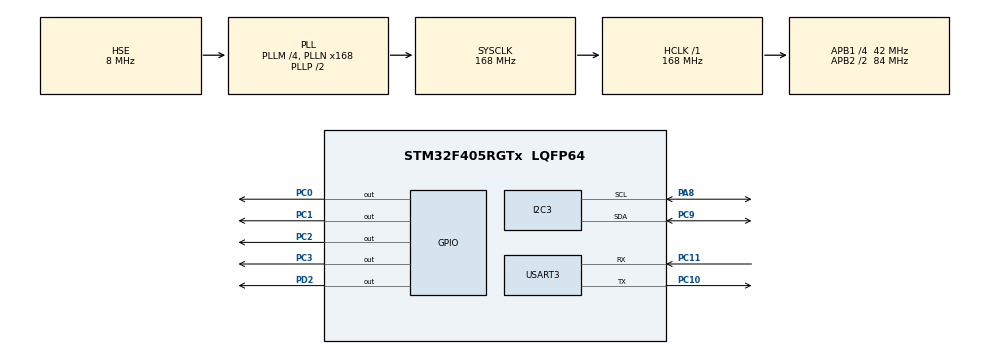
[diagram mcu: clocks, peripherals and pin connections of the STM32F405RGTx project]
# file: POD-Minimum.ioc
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Dma.I2C3_RX.0.Direction=DMA_PERIPH_TO_MEMORY
Dma.I2C3_RX.0.FIFOMode=DMA_FIFOMODE_DISABLE
Dma.I2C3_RX.0.Instance=DMA1_Stream2
Dma.I2C3_RX.0.MemDataAlignment=DMA_MDATAALIGN_BYTE
Dma.I2C3_RX.0.MemInc=DMA_MINC_ENABLE
Dma.I2C3_RX.0.Mode=DMA_NORMAL
Dma.I2C3_RX.0.PeriphDataAlignment=DMA_PDATAALIGN_BYTE
Dma.I2C3_RX.0.PeriphInc=DMA_PINC_DISABLE
Dma.I2C3_RX.0.Priority=DMA_PRIORITY_LOW
Dma.Request0=I2C3_RX
FREERTOS.Tasks01=defaultTask,24,150,StartDefaultTask,Default,NULL,Dynamic,NULL,NULL
FREERTOS.configENABLE_FPU=1
FREERTOS.configIDLE_SHOULD_YIELD=1
FREERTOS.configMINIMAL_STACK_SIZE=150
FREERTOS.configUSE_IDLE_HOOK=1
I2C3.I2C_Mode=I2C_Fast
I2C3.OwnAddress=0
Mcu.Family=STM32F4
Mcu.Name=STM32F405RGTx
Mcu.Package=LQFP64
NVIC.DMA1_Stream2_IRQn=true\:7\:0\:true\:false\:true\:true\:false\:true\:true
NVIC.I2C3_ER_IRQn=true\:7\:0\:true\:false\:true\:true\:true\:true\:true
NVIC.I2C3_EV_IRQn=true\:7\:0\:true\:false\:true\:true\:true\:true\:true
NVIC.PriorityGroup=NVIC_PRIORITYGROUP_4
NVIC.TIM6_DAC_IRQn=true\:15\:0\:false\:false\:true\:false\:false\:true\:true
NVIC.TIM7_IRQn=true\:5\:0\:true\:false\:true\:true\:true\:true\:true
NVIC.TimeBase=TIM6_DAC_IRQn
NVIC.TimeBaseIP=TIM6
NVIC.USART3_IRQn=true\:5\:0\:false\:false\:true\:true\:true\:true\:true
PA8.Mode=I2C
PA8.Signal=I2C3_SCL
PC0.GPIO_Speed=GPIO_SPEED_FREQ_MEDIUM
PC0.Signal=GPIO_Output
PC1.GPIO_Speed=GPIO_SPEED_FREQ_MEDIUM
PC1.Signal=GPIO_Output
PC10.Mode=Asynchronous
PC10.Signal=USART3_TX
PC11.Mode=Asynchronous
PC11.Signal=USART3_RX
PC2.GPIO_Speed=GPIO_SPEED_FREQ_MEDIUM
PC2.Signal=GPIO_Output
PC3.GPIO_Speed=GPIO_SPEED_FREQ_MEDIUM
PC3.Signal=GPIO_Output
PC9.Mode=I2C
PC9.Signal=I2C3_SDA
PD2.Signal=GPIO_Output
PH0-OSC_IN.Mode=HSE-External-Oscillator
PH0-OSC_IN.Signal=RCC_OSC_IN
PH1-OSC_OUT.Mode=HSE-External-Oscillator
PH1-OSC_OUT.Signal=RCC_OSC_OUT
ProjectManager.HeapSize=0x200
ProjectManager.StackSize=0x400
ProjectManager.TargetToolchain=Makefile
RCC.48MHZClocksFreq_Value=48000000
RCC.AHBFreq_Value=168000000
RCC.APB1CLKDivider=RCC_HCLK_DIV4
RCC.APB1Freq_Value=42000000
RCC.APB1TimFreq_Value=84000000
RCC.APB2CLKDivider=RCC_HCLK_DIV2
RCC.APB2Freq_Value=84000000
RCC.APB2TimFreq_Value=168000000
RCC.CortexFreq_Value=168000000
RCC.HCLKFreq_Value=168000000
RCC.HSE_VALUE=8000000
RCC.HSI_VALUE=16000000
RCC.LSE_VALUE=32768
RCC.PLLM=4
RCC.PLLN=168
RCC.PLLQ=7
RCC.PLLSourceVirtual=RCC_PLLSOURCE_HSE
RCC.SYSCLKFreq_VALUE=168000000
RCC.SYSCLKSource=RCC_SYSCLKSOURCE_PLLCLK
RCC.VCOOutputFreq_Value=336000000
TIM7.Prescaler=84
TIM7.TIM_MasterOutputTrigger=TIM_TRGO_RESET
USART3.VirtualMode=VM_ASYNC
VP_FREERTOS_VS_CMSIS_V2.Mode=CMSIS_V2
VP_SYS_VS_tim6.Mode=TIM6
VP_TIM7_VS_ClockSourceINT.Mode=Enable_Timer
board=custom

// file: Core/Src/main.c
/* USER CODE BEGIN Header */
/**
  ******************************************************************************
  * @file           : main.c
  * @brief          : Main program body
  ******************************************************************************
  * @attention
  *
  * Copyright (c) 2023 STMicroelectronics.
  * All rights reserved.
  *
  * This software is licensed under terms that can be found in the LICENSE file
  * in the root directory of this software component.
  * If no LICENSE file comes with this software, it is provided AS-IS.
  *
  ******************************************************************************
  */
/* USER CODE END Header */
#include "main.h"
#include "cmsis_os.h"
#include "dma.h"
#include "i2c.h"
#include "tim.h"
#include "usart.h"
#include "gpio.h"

void SystemClock_Config(void);
void MX_FREERTOS_Init(void);

int main(void)
{

  /* MCU Configuration--------------------------------------------------------*/

  /* Reset of all peripherals, Initializes the Flash interface and the Systick. */
  HAL_Init();

  /* Configure the system clock */
  SystemClock_Config();

  /* Initialize all configured peripherals */
  MX_GPIO_Init();
  MX_USART3_UART_Init();
  MX_DMA_Init();
  MX_TIM7_Init();
  MX_I2C3_Init();

  /* Init scheduler */
  osKernelInitialize();  /* Call init function for freertos objects (in freertos.c) */
  MX_FREERTOS_Init();

  /* Start scheduler */
  osKernelStart();

  /* We should never get here as control is now taken by the scheduler */
  /* Infinite loop */
  while (1)
  {

  }
}

void SystemClock_Config(void)
{
  RCC_OscInitTypeDef RCC_OscInitStruct = {0};
  RCC_ClkInitTypeDef RCC_ClkInitStruct = {0};

  /** Configure the main internal regulator output voltage
  */
  __HAL_RCC_PWR_CLK_ENABLE();
  __HAL_PWR_VOLTAGESCALING_CONFIG(PWR_REGULATOR_VOLTAGE_SCALE1);

  /** Initializes the RCC Oscillators according to the specified parameters
  * in the RCC_OscInitTypeDef structure.
  */
  RCC_OscInitStruct.OscillatorType = RCC_OSCILLATORTYPE_HSE;
  RCC_OscInitStruct.HSEState = RCC_HSE_ON;
  RCC_OscInitStruct.PLL.PLLState = RCC_PLL_ON;
  RCC_OscInitStruct.PLL.PLLSource = RCC_PLLSOURCE_HSE;
  RCC_OscInitStruct.PLL.PLLM = 4;
  RCC_OscInitStruct.PLL.PLLN = 168;
  RCC_OscInitStruct.PLL.PLLP = RCC_PLLP_DIV2;
  RCC_OscInitStruct.PLL.PLLQ = 7;
  if (HAL_RCC_OscConfig(&RCC_OscInitStruct) != HAL_OK)
  {
    Error_Handler();
  }

  /** Initializes the CPU, AHB and APB buses clocks
  */
  RCC_ClkInitStruct.ClockType = RCC_CLOCKTYPE_HCLK|RCC_CLOCKTYPE_SYSCLK
                              |RCC_CLOCKTYPE_PCLK1|RCC_CLOCKTYPE_PCLK2;
  RCC_ClkInitStruct.SYSCLKSource = RCC_SYSCLKSOURCE_PLLCLK;
  RCC_ClkInitStruct.AHBCLKDivider = RCC_SYSCLK_DIV1;
  RCC_ClkInitStruct.APB1CLKDivider = RCC_HCLK_DIV4;
  RCC_ClkInitStruct.APB2CLKDivider = RCC_HCLK_DIV2;

  if (HAL_RCC_ClockConfig(&RCC_ClkInitStruct, FLASH_LATENCY_5) != HAL_OK)
  {
    Error_Handler();
  }
}

void HAL_TIM_PeriodElapsedCallback(TIM_HandleTypeDef *htim)
{
  if (htim->Instance == TIM6) {
    HAL_IncTick();
  }
}

void Error_Handler(void)
{
  __disable_irq();
  while (1)
  {
  }
}

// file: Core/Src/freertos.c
/* USER CODE BEGIN Header */
/**
  ******************************************************************************
  * File Name          : freertos.c
  * Description        : Code for freertos applications
  ******************************************************************************
  * @attention
  *
  * Copyright (c) 2023 STMicroelectronics.
  * All rights reserved.
  *
  * This software is licensed under terms that can be found in the LICENSE file
  * in the root directory of this software component.
  * If no LICENSE file comes with this software, it is provided AS-IS.
  *
  ******************************************************************************
  */
/* USER CODE END Header */

#include "FreeRTOS.h"
#include "task.h"
#include "main.h"
#include "cmsis_os.h"

/* USER CODE BEGIN Includes */
#include "_i2c.h"
#include "debug.h"
/* USER CODE END Includes */

/* Definitions for defaultTask */
osThreadId_t defaultTaskHandle;
const osThreadAttr_t defaultTask_attributes = {
  .name = "defaultTask",
  .stack_size = 150 * 4,
  .priority = (osPriority_t) osPriorityNormal,
};

void StartDefaultTask(void *argument);

void MX_FREERTOS_Init(void); /* (MISRA C 2004 rule 8.1) */

/* Hook prototypes */
void vApplicationIdleHook(void);

/* USER CODE BEGIN 2 */
void vApplicationIdleHook( void )
{
   /* vApplicationIdleHook() will only be called if configUSE_IDLE_HOOK is set
   to 1 in FreeRTOSConfig.h. It will be called on each iteration of the idle
   task. It is essential that code added to this hook function never attempts
   to block in any way (for example, call xQueueReceive() with a block time
   specified, or call vTaskDelay()). If the application makes use of the
   vTaskDelete() API function (as this demo application does) then it is also
   important that vApplicationIdleHook() is permitted to return to its calling
   function, because it is the responsibility of the idle task to clean up
   memory allocated by the kernel to any task that has since been deleted. */
}
/* USER CODE END 2 */

void MX_FREERTOS_Init(void) {

  /* Create the thread(s) */
  /* creation of defaultTask */
  defaultTaskHandle = osThreadNew(StartDefaultTask, NULL, &defaultTask_attributes);

}

void StartDefaultTask(void *argument)
{
  /* USER CODE BEGIN StartDefaultTask */
  /* Infinite loop */
  uint8_t data[6];
  uint8_t addr = 0x18;
  for(;;)
  {
    i2cSensorsRead(0x0, data, 6, &addr);
    DEBUG_PRINT_UART("a");
    osDelay(1);
  }
  /* USER CODE END StartDefaultTask */
}
